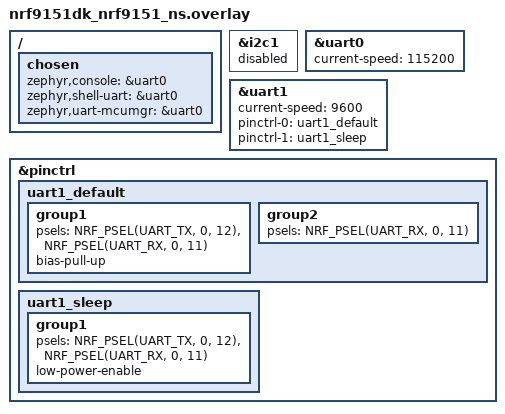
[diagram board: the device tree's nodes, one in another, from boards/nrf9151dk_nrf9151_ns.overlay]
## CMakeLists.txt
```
cmake_minimum_required(VERSION 3.20.0)

find_package(Zephyr REQUIRED HINTS $ENV{ZEPHYR_BASE})
project(testing)


target_sources(app PRIVATE
  src/main.c
)


target_include_directories(app PRIVATE
  ${CMAKE_CURRENT_SOURCE_DIR}/c_library_v2-master
)
```

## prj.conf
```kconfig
CONFIG_GPIO=y


CONFIG_SERIAL=y
CONFIG_PRINTK=y
CONFIG_UART_ASYNC_API=y
CONFIG_MAIN_STACK_SIZE=8096
```

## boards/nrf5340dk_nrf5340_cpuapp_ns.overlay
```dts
&pinctrl {
  uart1_default: uart1_default {
    group1 { psels = <NRF_PSEL(UART_TX, 1, 1)>; };
    group2 { psels = <NRF_PSEL(UART_RX, 1, 0)>; bias-pull-up; };
  };
  uart1_sleep: uart1_sleep {
    group1 {
      psels = <NRF_PSEL(UART_TX, 1, 1)>, <NRF_PSEL(UART_RX, 1, 0)>;
      low-power-enable;
    };
  };
};
&uart1 {
  status = "okay";
  current-speed = <115200>;
  pinctrl-0 = <&uart1_default>;
  pinctrl-1 = <&uart1_sleep>;
  pinctrl-names = "default","sleep";
};
```

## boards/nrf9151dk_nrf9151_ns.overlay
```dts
/ {
    chosen {
        zephyr,console = &uart0;
        zephyr,shell-uart = &uart0;
        zephyr,uart-mcumgr = &uart0;
    };
};




&i2c1 {
  status = "disabled";
};

&uart0 {
    status = "okay";
    current-speed = <115200>;
};


&uart1 {
    status = "okay";
    current-speed = <9600>;
    pinctrl-0 = <&uart1_default>;
	pinctrl-1 = <&uart1_sleep>;
    pinctrl-names = "default", "sleep";
};

&pinctrl {
	uart1_default: uart1_default {
		group1 {
			psels = <NRF_PSEL(UART_TX, 0, 12)>,  
			        <NRF_PSEL(UART_RX, 0, 11)>;  
			bias-pull-up;                      /* keep RX idle-high */
		};

        group2 {
            psels = <NRF_PSEL(UART_RX, 0, 11)>;  
        };
	};
	uart1_sleep: uart1_sleep {
		group1 {
			psels = <NRF_PSEL(UART_TX, 0, 12)>,  
			        <NRF_PSEL(UART_RX, 0, 11)>; 
			low-power-enable;
		};
	};
};
```

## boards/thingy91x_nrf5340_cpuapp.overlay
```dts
/ {
    chosen {
        zephyr,console = &cdc_acm_uart0;
        zephyr,shell-uart = &cdc_acm_uart0;
        zephyr,uart-mcumgr = &cdc_acm_uart0;
    };
};
&uart0		  { status = "okay"; };
&uart1        {status = "okay";};    
&usbd          { status = "okay"; };


&zephyr_udc0 {
	cdc_acm_uart0: cdc_acm_uart0 {
		compatible = "zephyr,cdc-acm-uart";
	};

	cdc_acm_uart1: cdc_acm_uart1 {
		compatible = "zephyr,cdc-acm-uart";
	};
};
```

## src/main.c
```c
#include <zephyr/kernel.h>
#include <zephyr/drivers/gpio.h>
#include <zephyr/sys/printk.h>
#include "ardupilotmega/mavlink.h"
#include <zephyr/device.h>
#include <zephyr/drivers/uart.h>
#include <zephyr/kernel.h>
#include <stddef.h>
#include <stdint.h>

#include <nrfx_uarte.h>
#include <hal/nrf_gpio.h>

#define UARTE_INST  1
#define TX_PIN  6
#define RX_PIN  7

#define UART_DEVICE_NODE DT_NODELABEL(uart1)
static const struct device *const uart_dev = DEVICE_DT_GET(UART_DEVICE_NODE);


#define SYSID 1 
#define COMPID MAV_COMP_ID_MISSIONPLANNER
#define TARGET_SYS  1 
#define TARGET_COMP 1


static void uart_cb(const struct device *dev, struct uart_event *evt, void *user_data)
{
	switch (evt->type) {
	
	case UART_TX_DONE:
		// do something
        //printk("UART_TX_DONE\n");
		break;

	case UART_TX_ABORTED:
		// do something
        printk("UART_TX_ABORTED\n");
		break;
		
	case UART_RX_RDY:
		// do something
		break;

	case UART_RX_BUF_REQUEST:
		// do something
		break;

	case UART_RX_BUF_RELEASED:
		// do something
		break;
		
	case UART_RX_DISABLED:
		// do something
		break;

	case UART_RX_STOPPED:
		// do something
		break;
		
	default:
		break;
	}
}

void Send(const uint8_t *buf, size_t len)
{
    
    if (uart_tx(uart_dev, buf, len, SYS_FOREVER_MS) != 0) {
        printk("uart_tx failed\n");
    }
    
} 

void SendHeartbeat(void) {

    mavlink_message_t msg;
    uint8_t buf[MAVLINK_MAX_PACKET_LEN];

    mavlink_msg_heartbeat_pack(
        SYSID,         
        COMPID,           
        &msg,
        MAV_TYPE_ONBOARD_CONTROLLER,
        MAV_AUTOPILOT_INVALID,
        0, 0,
        MAV_STATE_ACTIVE
    );

    size_t len = mavlink_msg_to_send_buffer(buf, &msg);
    Send(buf, len);
    //printk("%d \n", buf);
    printk("Sending Heartbeat\n");
}

int main(void)
{
    
    printk("nRF5340 blinky running\n");
    if (!device_is_ready(uart_dev)) {
        return;
    }
    int err;
    err = uart_callback_set(uart_dev, uart_cb, NULL);
    if (err) {
        return err;
    }
    while (1) {
        SendHeartbeat();
        k_msleep(50);
    }
}
```
